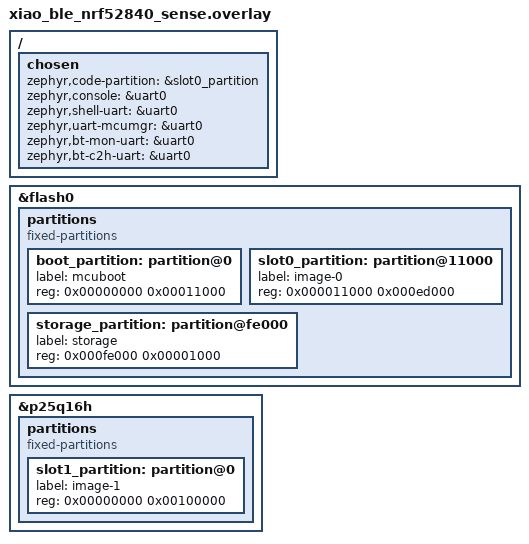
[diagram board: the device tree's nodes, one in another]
/delete-node/ &boot_partition;
/delete-node/ &storage_partition;
/delete-node/ &code_partition;
/delete-node/ &sd_partition;

/ {
    chosen {
        zephyr,code-partition = &slot0_partition;
		zephyr,console = &uart0;
		zephyr,shell-uart = &uart0;
		zephyr,uart-mcumgr = &uart0;
		zephyr,bt-mon-uart = &uart0;
		zephyr,bt-c2h-uart = &uart0;
    };
};

&flash0 {
    partitions {
		compatible = "fixed-partitions";
		#address-cells = <1>;
		#size-cells = <1>;

		boot_partition: partition@0 {
			label = "mcuboot";
			reg = <0x00000000 0x00011000>;
		};

		slot0_partition: partition@11000 {
			label = "image-0";
			reg = <0x000011000 0x000ed000>;
		};

		/*
		 * The flash starting at 0x000f8000 and ending at
		 * 0x000fffff is reserved for use by the application.
		 */

		/*
		 * Storage partition will be used by FCB/LittleFS/NVS
		 * if enabled.
		 */
		storage_partition: partition@fe000 {
			label = "storage";
			reg = <0x000fe000 0x00001000>;
		};
	};
};

&p25q16h {
    status="okay";
    partitions {
        compatible = "fixed-partitions";
        #address-cells = <0x1>;
        #size-cells=<0x1>;

        slot1_partition: partition@0 {
			label = "image-1";
			reg = <0x00000000 0x00100000>;
		};
    };
};
